# STM32H5E4 register map
File version: 1.0
CPU: CM33 r0p0, little endian, MPU, FPU, 4 interrupt priority bits
Registers are 32-bit, read-write, reset 0x0 unless marked. A register's access mark holds for its fields unless they carry their own. Offsets are from the block's base; [hi:lo] are bit positions; {n}, {i} and the like mark numbered series.

## IWDG — IWDG address block description
Base 0x40003000
Same registers: IWDG_S 0x50003000
0x00 IWDG_KR wo — IWDG key register
  [15:0] KEY — Key value (write only, read 0x0000)
0x04 IWDG_PR — IWDG prescaler register
  [3:0] PR — Prescaler divider
    0=divider / 4; 1=divider / 8; 2=divider / 16; 3=divider / 32; 4=divider / 64; 5=divider / 128; 6=divider / 256; 7=divider / 512
0x08 IWDG_RLR reset 0xFFF — IWDG reload register
  [11:0] RL — Watchdog counter reload value
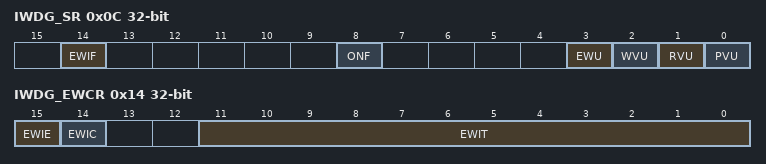
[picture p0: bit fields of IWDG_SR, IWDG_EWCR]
0x0C IWDG_SR ro — IWDG status register
  [14] EWIF — Watchdog early interrupt flag
  [8] ONF — Watchdog enable status bit
    0=The IWDG is not activated; 1=The IWDG is activated and needs to be refreshed regularly by the application
  [3] EWU — Watchdog interrupt comparator value update
  [2] WVU — Watchdog counter window value update
  [1] RVU — Watchdog counter reload value update
  [0] PVU — Watchdog prescaler value update
0x10 IWDG_WINR reset 0xFFF — IWDG window register
  [11:0] WIN — Watchdog counter window value
0x14 IWDG_EWCR — IWDG early wake-up interrupt register
  [15] EWIE — Watchdog early interrupt enable
    0=The early interrupt interface is disabled; 1=The early interrupt interface is enabled
  [14] EWIC wo — Watchdog early interrupt acknowledge
  [11:0] EWIT — Watchdog counter window value

## OCTOSPIM — OCTOSPIM register block
Base 0x47003400
Same registers: OCTOSPIM_S 0x57003400
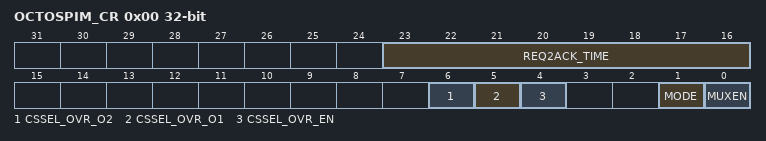
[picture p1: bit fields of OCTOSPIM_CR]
0x00 OCTOSPIM_CR — OCTOSPIM control register
  [23:16] REQ2ACK_TIME — REQ to ACK time
  [6] CSSEL_OVR_O2 — Chip select selector override setting for OCTOSPI2
    0=the chip select signal from OCTOSPI2 is sent to NCS1; 1=the chip select signal from OCTOSPI2 is sent to NCS2
  [5] CSSEL_OVR_O1 — Chip select selector override setting for OCTOSPI1
    0=the chip select signal from OCTOSPI1 is sent to NCS1; 1=the chip select signal from OCTOSPI1 is sent to NCS2
  [4] CSSEL_OVR_EN — Chip select selector override enable
    0=override not enabled; 1=CSSEL_OVR_O1 and CSSEL_OVR_O2 bit values overwrite the CSSEL signal values coming from OCTOSPI1 and OCTOSPI2
  [1] MODE — OCTOSPIM multiplexing mode
    0=if MUXEN = 0 direct mode, if MUXEN = 1 arbitration mode to output Port 1; 1=if MUXEN = 0 swapped mode, if MUXEN = 1 arbitration mode to output Port 2
  [0] MUXEN — Multiplexed mode enable
    0=No multiplexing, hence no arbitration; 1=OCTOSPI1 and OCTOSPI2 are multiplexed over the same bus

## OPAMP1 — OPAMP1 address block description
Base 0x40003400
Same registers: OPAMP1_S 0x50003400
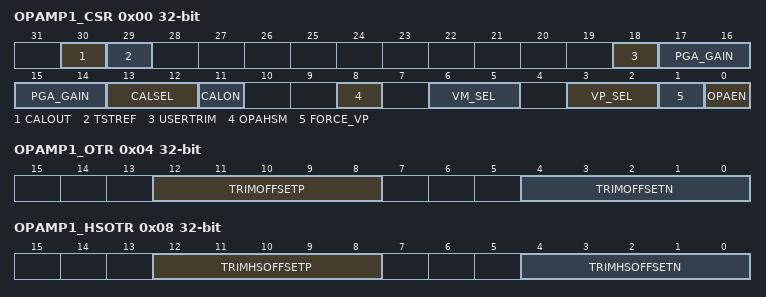
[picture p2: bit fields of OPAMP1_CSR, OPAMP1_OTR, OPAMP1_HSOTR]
0x00 OPAMP1_CSR — OPAMP1 control/status register
  [30] CALOUT ro — Operational amplifier calibration output
    0=Noninverting less than inverting; 1=Noninverting > inverting
  [29] TSTREF — OPAMP calibration reference voltage output control (reserved for test)
    0=INTVREF of OPAMP is not output; 1=INTVREF of OPAMP is output
  [18] USERTRIM — User trimming enable
    0=factory' trim code used; 1=user' trim code used
  [17:14] PGA_GAIN — Programmable gain amplifier gain setting
    0=Noninverting internal gain 2, VREF-referenced; 1=Noninverting internal gain 4, VREF-referenced; 2=Noninverting internal gain 8, VREF-referenced; 3=Noninverting internal gain 16, VREF-referenced; 4=Noninverting internal gain 2 with filtering on INM0, VREF-referenced; 5=Noninverting internal gain 4 with filtering on INM0, VREF-referenced; 6=Noninverting internal gain 8 with filtering on INM0, VREF-referenced; 7=Noninverting internal gain 16 with filtering on INM0, VREF-referenced; 8=Inverting gain=-1/ Noninverting gain =2 with INM0 node for input or bias; 9=Inverting gain=-3/ Noninverting gain =4 with INM0 node for input or bias; 10=Inverting gain=-7/ Noninverting gain =8 with INM0 node for input or bias; 11=Inverting gain=-15/ Noninverting gain =16 with INM0 node for input or bias; 12=Inverting gain=-1/ Noninverting gain =2 with INM0 node for input or bias, INM1 node for filtering; 13=Inverting gain=-3/ Noninverting gain =4 with INM0 node for input or bias, INM1 node for filtering; 14=Inverting gain=-7/ Noninverting gain =8 with INM0 node for input or bias, INM1 node for filtering; 15=Inverting gain=-15/ Noninverting gain =16 with INM0 node for input or bias, INM1 node for filtering
  [13:12] CALSEL — Calibration selection
    {v}=0 (v=0..3)
  [11] CALON — Calibration mode enabled
    0=Normal mode; 1=Calibration mode (all switches opened by HW)
  [8] OPAHSM — Operational amplifier high-speed mode
    0=operational amplifier in normal mode; 1=operational amplifier in high-speed mode
  [6:5] VM_SEL — Inverting input selection
    0=INM0 connected to OPAMP_VINM input; 1=INM1 connected to OPAMP_VINM input; 2=Feedback resistor is connected to the OPAMP_VINM input (PGA mode), Inverting input selection depends on the PGA_GAIN setting; 3=opamp_out connected to OPAMP_VINM input (Follower mode)
  [3:2] VP_SEL — Non inverted input selection
    0=GPIO INP0 connected to OPAMP_VINP; 1=dac_out1 connected to OPAMP_VINP; 2=GPIO INP2 is connected to OPAMP_VINP
  [1] FORCE_VP — Force internal reference on VP (reserved for test)
    0=Normal operating mode; 1=Calibration verification mode: Noninverting input connected to calibration reference voltage
  [0] OPAEN — Operational amplifier enable
    0=operational amplifier disabled; 1=operational amplifier enabled
0x04 OPAMP1_OTR (reset mask 0xFFFF0000) — OPAMP1 trimming register in normal mode
  [12:8] TRIMOFFSETP — Trim for PMOS differential pairs
  [4:0] TRIMOFFSETN — Trim for NMOS differential pairs
0x08 OPAMP1_HSOTR (reset mask 0xFFFF0000) — OPAMP1 trimming register in high-speed mode
  [12:8] TRIMHSOFFSETP — High-speed mode trim for PMOS differential pairs
  [4:0] TRIMHSOFFSETN — High-speed mode trim for NMOS differential pairs
